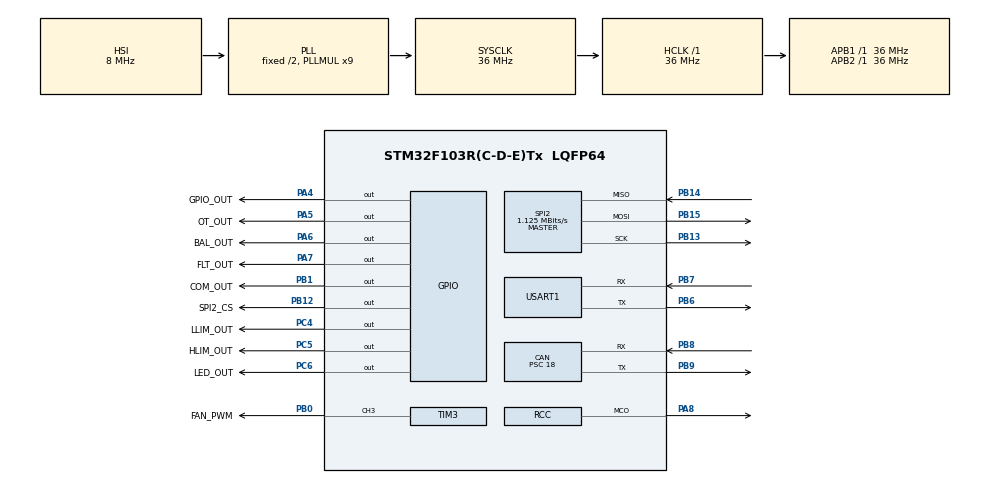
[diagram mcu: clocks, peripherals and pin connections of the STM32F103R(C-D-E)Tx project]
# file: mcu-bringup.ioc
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CAN.BS1=CAN_BS1_12TQ
CAN.BS2=CAN_BS2_3TQ
CAN.CalculateBaudRate=125000
CAN.CalculateTimeBit=8000
CAN.CalculateTimeQuantum=500.0
CAN.NART=DISABLE
CAN.Prescaler=18
CAN.TXFP=ENABLE
Mcu.Family=STM32F1
Mcu.Name=STM32F103R(C-D-E)Tx
Mcu.Package=LQFP64
NVIC.PriorityGroup=NVIC_PRIORITYGROUP_4
PA13.Mode=Serial_Wire
PA13.Signal=SYS_JTMS-SWDIO
PA14.Mode=Serial_Wire
PA14.Signal=SYS_JTCK-SWCLK
PA4.GPIO_Label=GPIO_OUT
PA4.Signal=GPIO_Output
PA5.GPIO_Label=OT_OUT
PA5.Signal=GPIO_Output
PA6.GPIO_Label=BAL_OUT
PA6.Signal=GPIO_Output
PA7.GPIO_Label=FLT_OUT
PA7.Signal=GPIO_Output
PA8.Mode=Clock-out
PA8.Signal=RCC_MCO
PB0.GPIO_Label=FAN_PWM
PB0.Signal=S_TIM3_CH3
PB1.GPIO_Label=COM_OUT
PB1.Signal=GPIO_Output
PB12.GPIO_Label=SPI2_CS
PB12.Signal=GPIO_Output
PB13.Mode=Full_Duplex_Master
PB13.Signal=SPI2_SCK
PB14.Mode=Full_Duplex_Master
PB14.Signal=SPI2_MISO
PB15.Mode=Full_Duplex_Master
PB15.Signal=SPI2_MOSI
PB6.Mode=Asynchronous
PB6.Signal=USART1_TX
PB7.Mode=Asynchronous
PB7.Signal=USART1_RX
PB8.Mode=CAN_Activate
PB8.Signal=CAN_RX
PB9.Mode=CAN_Activate
PB9.Signal=CAN_TX
PC4.GPIO_Label=LLIM_OUT
PC4.Signal=GPIO_Output
PC5.GPIO_Label=HLIM_OUT
PC5.Signal=GPIO_Output
PC6.GPIO_Label=LED_OUT
PC6.Signal=GPIO_Output
PD0-OSC_IN.Mode=HSE-External-Oscillator
PD0-OSC_IN.Signal=RCC_OSC_IN
PD1-OSC_OUT.Mode=HSE-External-Oscillator
PD1-OSC_OUT.Signal=RCC_OSC_OUT
ProjectManager.HeapSize=0x200
ProjectManager.StackSize=0x400
ProjectManager.TargetToolchain=Makefile
RCC.AHBFreq_Value=36000000
RCC.APB1Freq_Value=36000000
RCC.APB1TimFreq_Value=36000000
RCC.APB2Freq_Value=36000000
RCC.APB2TimFreq_Value=36000000
RCC.HCLKFreq_Value=36000000
RCC.PLLMUL=RCC_PLL_MUL9
RCC.RCC_MCOSource=RCC_MCO1SOURCE_HSI
RCC.SYSCLKFreq_VALUE=36000000
RCC.SYSCLKSource=RCC_SYSCLKSOURCE_PLLCLK
RCC.USBFreq_Value=36000000
SH.S_TIM3_CH3.0=TIM3_CH3,PWM Generation3 CH3
SPI2.BaudRatePrescaler=SPI_BAUDRATEPRESCALER_32
SPI2.CLKPhase=SPI_PHASE_2EDGE
SPI2.CLKPolarity=SPI_POLARITY_HIGH
SPI2.CalculateBaudRate=1.125 MBits/s
SPI2.Direction=SPI_DIRECTION_2LINES
SPI2.Mode=SPI_MODE_MASTER
SPI2.VirtualType=VM_MASTER
TIM3.Channel-PWM\ Generation3\ CH3=TIM_CHANNEL_3
TIM3.Period=99
TIM3.Prescaler=35999
TIM3.Pulse-PWM\ Generation3\ CH3=0
TIM3.TIM_MasterOutputTrigger=TIM_TRGO_UPDATE
USART1.VirtualMode=VM_ASYNC
board=custom

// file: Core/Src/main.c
/* USER CODE BEGIN Header */
/**
  ******************************************************************************
  * @file           : main.c
  * @brief          : Main program body
  ******************************************************************************
  * @attention
  *
  * Copyright (c) 2022 STMicroelectronics.
  * All rights reserved.
  *
  * This software is licensed under terms that can be found in the LICENSE file
  * in the root directory of this software component.
  * If no LICENSE file comes with this software, it is provided AS-IS.
  *
  ******************************************************************************
  */
/* USER CODE END Header */
#include "main.h"

/* USER CODE BEGIN Includes */
#include "debug_io.h"
#include "bringup_test.h"
/* USER CODE END Includes */

CAN_HandleTypeDef hcan;

SPI_HandleTypeDef hspi2;

TIM_HandleTypeDef htim3;

UART_HandleTypeDef huart1;

void SystemClock_Config(void);
static void MX_GPIO_Init(void);
static void MX_CAN_Init(void);
static void MX_SPI2_Init(void);
static void MX_TIM3_Init(void);
static void MX_USART1_UART_Init(void);

int main(void)
{

  /* MCU Configuration--------------------------------------------------------*/

  /* Reset of all peripherals, Initializes the Flash interface and the Systick. */
  HAL_Init();

  /* Configure the system clock */
  SystemClock_Config();

  /* Initialize all configured peripherals */
  MX_GPIO_Init();
  MX_CAN_Init();
  MX_SPI2_Init();
  MX_TIM3_Init();
  MX_USART1_UART_Init();
  /* USER CODE BEGIN 2 */
  DebugIO_init(&huart1);
  HAL_GPIO_WritePin(SPI2_CS_GPIO_Port, SPI2_CS_Pin, 1);
  HAL_TIM_PWM_Start(&htim3, TIM_CHANNEL_3);
  HAL_CAN_Start(&hcan);
  /* USER CODE END 2 */

  /* Infinite loop */
  /* USER CODE BEGIN WHILE */
  while (1)
  {
    // Pick one function to uncomment at a time
    BringupTest_blinkLed();
    // BringupTest_gpioSequence();
    // BringupTest_fanPwm(&htim3);
    // BringupTest_spiTx(&hspi2);
    // BringupTest_canTx(&hcan);
    // BringupTest_uartTx();
    /* USER CODE END WHILE */

  }
}

void SystemClock_Config(void)
{
  RCC_OscInitTypeDef RCC_OscInitStruct = {0};
  RCC_ClkInitTypeDef RCC_ClkInitStruct = {0};

  /** Initializes the RCC Oscillators according to the specified parameters
  * in the RCC_OscInitTypeDef structure.
  */
  RCC_OscInitStruct.OscillatorType = RCC_OSCILLATORTYPE_HSI;
  RCC_OscInitStruct.HSIState = RCC_HSI_ON;
  RCC_OscInitStruct.HSICalibrationValue = RCC_HSICALIBRATION_DEFAULT;
  RCC_OscInitStruct.PLL.PLLState = RCC_PLL_ON;
  RCC_OscInitStruct.PLL.PLLSource = RCC_PLLSOURCE_HSI_DIV2;
  RCC_OscInitStruct.PLL.PLLMUL = RCC_PLL_MUL9;
  if (HAL_RCC_OscConfig(&RCC_OscInitStruct) != HAL_OK)
  {
    Error_Handler();
  }

  /** Initializes the CPU, AHB and APB buses clocks
  */
  RCC_ClkInitStruct.ClockType = RCC_CLOCKTYPE_HCLK|RCC_CLOCKTYPE_SYSCLK
                              |RCC_CLOCKTYPE_PCLK1|RCC_CLOCKTYPE_PCLK2;
  RCC_ClkInitStruct.SYSCLKSource = RCC_SYSCLKSOURCE_PLLCLK;
  RCC_ClkInitStruct.AHBCLKDivider = RCC_SYSCLK_DIV1;
  RCC_ClkInitStruct.APB1CLKDivider = RCC_HCLK_DIV1;
  RCC_ClkInitStruct.APB2CLKDivider = RCC_HCLK_DIV1;

  if (HAL_RCC_ClockConfig(&RCC_ClkInitStruct, FLASH_LATENCY_1) != HAL_OK)
  {
    Error_Handler();
  }
  HAL_RCC_MCOConfig(RCC_MCO, RCC_MCO1SOURCE_HSI, RCC_MCODIV_1);
}

static void MX_CAN_Init(void)
{

  hcan.Instance = CAN1;
  hcan.Init.Prescaler = 18;
  hcan.Init.Mode = CAN_MODE_NORMAL;
  hcan.Init.SyncJumpWidth = CAN_SJW_1TQ;
  hcan.Init.TimeSeg1 = CAN_BS1_12TQ;
  hcan.Init.TimeSeg2 = CAN_BS2_3TQ;
  hcan.Init.TimeTriggeredMode = DISABLE;
  hcan.Init.AutoBusOff = DISABLE;
  hcan.Init.AutoWakeUp = DISABLE;
  hcan.Init.AutoRetransmission = DISABLE;
  hcan.Init.ReceiveFifoLocked = DISABLE;
  hcan.Init.TransmitFifoPriority = ENABLE;
  if (HAL_CAN_Init(&hcan) != HAL_OK)
  {
    Error_Handler();
  }

}

static void MX_SPI2_Init(void)
{

  /* SPI2 parameter configuration*/
  hspi2.Instance = SPI2;
  hspi2.Init.Mode = SPI_MODE_MASTER;
  hspi2.Init.Direction = SPI_DIRECTION_2LINES;
  hspi2.Init.DataSize = SPI_DATASIZE_8BIT;
  hspi2.Init.CLKPolarity = SPI_POLARITY_HIGH;
  hspi2.Init.CLKPhase = SPI_PHASE_2EDGE;
  hspi2.Init.NSS = SPI_NSS_SOFT;
  hspi2.Init.BaudRatePrescaler = SPI_BAUDRATEPRESCALER_32;
  hspi2.Init.FirstBit = SPI_FIRSTBIT_MSB;
  hspi2.Init.TIMode = SPI_TIMODE_DISABLE;
  hspi2.Init.CRCCalculation = SPI_CRCCALCULATION_DISABLE;
  hspi2.Init.CRCPolynomial = 10;
  if (HAL_SPI_Init(&hspi2) != HAL_OK)
  {
    Error_Handler();
  }

}

static void MX_TIM3_Init(void)
{

  TIM_MasterConfigTypeDef sMasterConfig = {0};
  TIM_OC_InitTypeDef sConfigOC = {0};

  htim3.Instance = TIM3;
  htim3.Init.Prescaler = 35999;
  htim3.Init.CounterMode = TIM_COUNTERMODE_UP;
  htim3.Init.Period = 99;
  htim3.Init.ClockDivision = TIM_CLOCKDIVISION_DIV1;
  htim3.Init.AutoReloadPreload = TIM_AUTORELOAD_PRELOAD_DISABLE;
  if (HAL_TIM_PWM_Init(&htim3) != HAL_OK)
  {
    Error_Handler();
  }
  sMasterConfig.MasterOutputTrigger = TIM_TRGO_UPDATE;
  sMasterConfig.MasterSlaveMode = TIM_MASTERSLAVEMODE_DISABLE;
  if (HAL_TIMEx_MasterConfigSynchronization(&htim3, &sMasterConfig) != HAL_OK)
  {
    Error_Handler();
  }
  sConfigOC.OCMode = TIM_OCMODE_PWM1;
  sConfigOC.Pulse = 0;
  sConfigOC.OCPolarity = TIM_OCPOLARITY_HIGH;
  sConfigOC.OCFastMode = TIM_OCFAST_DISABLE;
  if (HAL_TIM_PWM_ConfigChannel(&htim3, &sConfigOC, TIM_CHANNEL_3) != HAL_OK)
  {
    Error_Handler();
  }
  HAL_TIM_MspPostInit(&htim3);

}

static void MX_USART1_UART_Init(void)
{

  huart1.Instance = USART1;
  huart1.Init.BaudRate = 115200;
  huart1.Init.WordLength = UART_WORDLENGTH_8B;
  huart1.Init.StopBits = UART_STOPBITS_1;
  huart1.Init.Parity = UART_PARITY_NONE;
  huart1.Init.Mode = UART_MODE_TX_RX;
  huart1.Init.HwFlowCtl = UART_HWCONTROL_NONE;
  huart1.Init.OverSampling = UART_OVERSAMPLING_16;
  if (HAL_UART_Init(&huart1) != HAL_OK)
  {
    Error_Handler();
  }

}

static void MX_GPIO_Init(void)
{
  GPIO_InitTypeDef GPIO_InitStruct = {0};

  /* GPIO Ports Clock Enable */
  __HAL_RCC_GPIOD_CLK_ENABLE();
  __HAL_RCC_GPIOA_CLK_ENABLE();
  __HAL_RCC_GPIOC_CLK_ENABLE();
  __HAL_RCC_GPIOB_CLK_ENABLE();

  /*Configure GPIO pin Output Level */
  HAL_GPIO_WritePin(GPIOA, GPIO_OUT_Pin|OT_OUT_Pin|BAL_OUT_Pin|FLT_OUT_Pin, GPIO_PIN_RESET);

  /*Configure GPIO pin Output Level */
  HAL_GPIO_WritePin(GPIOC, LLIM_OUT_Pin|HLIM_OUT_Pin|LED_OUT_Pin, GPIO_PIN_RESET);

  /*Configure GPIO pin Output Level */
  HAL_GPIO_WritePin(GPIOB, COM_OUT_Pin|SPI2_CS_Pin, GPIO_PIN_RESET);

  /*Configure GPIO pins : GPIO_OUT_Pin OT_OUT_Pin BAL_OUT_Pin FLT_OUT_Pin */
  GPIO_InitStruct.Pin = GPIO_OUT_Pin|OT_OUT_Pin|BAL_OUT_Pin|FLT_OUT_Pin;
  GPIO_InitStruct.Mode = GPIO_MODE_OUTPUT_PP;
  GPIO_InitStruct.Pull = GPIO_NOPULL;
  GPIO_InitStruct.Speed = GPIO_SPEED_FREQ_LOW;
  HAL_GPIO_Init(GPIOA, &GPIO_InitStruct);

  /*Configure GPIO pins : LLIM_OUT_Pin HLIM_OUT_Pin LED_OUT_Pin */
  GPIO_InitStruct.Pin = LLIM_OUT_Pin|HLIM_OUT_Pin|LED_OUT_Pin;
  GPIO_InitStruct.Mode = GPIO_MODE_OUTPUT_PP;
  GPIO_InitStruct.Pull = GPIO_NOPULL;
  GPIO_InitStruct.Speed = GPIO_SPEED_FREQ_LOW;
  HAL_GPIO_Init(GPIOC, &GPIO_InitStruct);

  /*Configure GPIO pins : COM_OUT_Pin SPI2_CS_Pin */
  GPIO_InitStruct.Pin = COM_OUT_Pin|SPI2_CS_Pin;
  GPIO_InitStruct.Mode = GPIO_MODE_OUTPUT_PP;
  GPIO_InitStruct.Pull = GPIO_NOPULL;
  GPIO_InitStruct.Speed = GPIO_SPEED_FREQ_LOW;
  HAL_GPIO_Init(GPIOB, &GPIO_InitStruct);

  /*Configure GPIO pin : PA8 */
  GPIO_InitStruct.Pin = GPIO_PIN_8;
  GPIO_InitStruct.Mode = GPIO_MODE_AF_PP;
  GPIO_InitStruct.Speed = GPIO_SPEED_FREQ_LOW;
  HAL_GPIO_Init(GPIOA, &GPIO_InitStruct);

}

void Error_Handler(void)
{
  __disable_irq();
  while (1)
  {
  }
}
